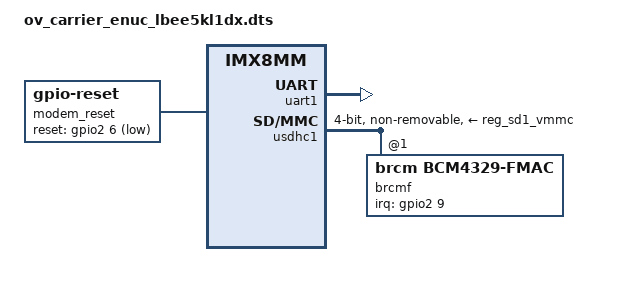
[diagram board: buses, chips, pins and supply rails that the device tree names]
/**
 * Portenta-M8 dtb overlay file
 * Arduino 2021
 * Enable modem LBEE5KL1DX serial on Arduino eNUC carrier board
 * with RTS CTS and modem reset
 * Gpios:
 * gpio-reset controls modem reset active low
 */

/dts-v1/;
/plugin/;

#include <dt-bindings/gpio/gpio.h>
#include <dt-bindings/interrupt-controller/arm-gic.h>
#include "imx8mm-pinfunc.h"

/ {
	compatible = "fsl,imx8mm-evk", "fsl,imx8mm";

	fragment@0 {
		target = <&iomuxc>;
		__overlay__ {
			imx8mm {
				pinctrl_uart1: uart1grp {
					fsl,pins = <
						MX8MM_IOMUXC_UART1_RXD_UART1_DCE_RX     0x140
						MX8MM_IOMUXC_UART1_TXD_UART1_DCE_TX     0x140
						MX8MM_IOMUXC_UART3_RXD_UART1_DCE_CTS_B  0x140
						MX8MM_IOMUXC_UART3_TXD_UART1_DCE_RTS_B  0x140
						MX8MM_IOMUXC_SD1_DATA4_GPIO2_IO6        0x19 // BT_REG_ON
					>;
				};

				pinctrl_usdhc1_gpio: usdhc1grpgpio {
					fsl,pins = <
						MX8MM_IOMUXC_SD1_RESET_B_GPIO2_IO10         0x41 // WL_REG_ON
						MX8MM_IOMUXC_GPIO1_IO00_ANAMIX_REF_CLK_32K  0x141 // REF_CLK_32K
					>;
				};

				pinctrl_usdhc1: usdhc1grp {
					fsl,pins = <
						MX8MM_IOMUXC_SD1_CLK_USDHC1_CLK		0x190
						MX8MM_IOMUXC_SD1_CMD_USDHC1_CMD		0x1d0
						MX8MM_IOMUXC_SD1_DATA0_USDHC1_DATA0	0x1d0
						MX8MM_IOMUXC_SD1_DATA1_USDHC1_DATA1	0x1d0
						MX8MM_IOMUXC_SD1_DATA2_USDHC1_DATA2	0x1d0
						MX8MM_IOMUXC_SD1_DATA3_USDHC1_DATA3	0x1d0
					>;
				};

				pinctrl_usdhc1_100mhz: usdhc1grp100mhz {
					fsl,pins = <
						MX8MM_IOMUXC_SD1_CLK_USDHC1_CLK		0x194
						MX8MM_IOMUXC_SD1_CMD_USDHC1_CMD		0x1d4
						MX8MM_IOMUXC_SD1_DATA0_USDHC1_DATA0	0x1d4
						MX8MM_IOMUXC_SD1_DATA1_USDHC1_DATA1	0x1d4
						MX8MM_IOMUXC_SD1_DATA2_USDHC1_DATA2	0x1d4
						MX8MM_IOMUXC_SD1_DATA3_USDHC1_DATA3	0x1d4
					>;
				};

				pinctrl_usdhc1_200mhz: usdhc1grp200mhz {
					fsl,pins = <
						MX8MM_IOMUXC_SD1_CLK_USDHC1_CLK		0x196
						MX8MM_IOMUXC_SD1_CMD_USDHC1_CMD		0x1d6
						MX8MM_IOMUXC_SD1_DATA0_USDHC1_DATA0	0x1d6
						MX8MM_IOMUXC_SD1_DATA1_USDHC1_DATA1	0x1d6
						MX8MM_IOMUXC_SD1_DATA2_USDHC1_DATA2	0x1d6
						MX8MM_IOMUXC_SD1_DATA3_USDHC1_DATA3	0x1d6
					>;
				};
			};
		};
	};

	modem_reset: modem-reset {
		compatible = "gpio-reset";
		reset-gpios = <&gpio2 6 GPIO_ACTIVE_LOW>;
		reset-delay-us = <2000>;
		reset-post-delay-ms = <40>;
		#reset-cells = <0>;
	};

	fragment@1 {
		target = <&uart1>;
		__overlay__ {
			pinctrl-names = "default";
			pinctrl-0 = <&pinctrl_uart1>;
			uart-has-rtscts;
			resets = <&modem_reset>;
			status = "okay";
		};
	};

	fragment@2 {
		target = <&usdhc1>;
		__overlay__ {
			#address-cells = <1>;
			#size-cells = <0>;
			pinctrl-names = "default", "state_100mhz", "state_200mhz";
			pinctrl-0 = <&pinctrl_usdhc1>, <&pinctrl_usdhc1_gpio>;
			pinctrl-1 = <&pinctrl_usdhc1_100mhz>, <&pinctrl_usdhc1_gpio>;
			pinctrl-2 = <&pinctrl_usdhc1_200mhz>, <&pinctrl_usdhc1_gpio>;
			bus-width = <4>;
			vmmc-supply = <&reg_sd1_vmmc>;
			pm-ignore-notify;
			keep-power-in-suspend;
			non-removable;
			status = "okay";

			brcmf: bcrmf@1 {
				reg = <1>;
				compatible = "brcm,bcm4329-fmac";
				interrupt-parent = <&gpio2>;
				interrupts = <9 IRQ_TYPE_LEVEL_HIGH>;
				interrupt-names = "host-wake";
			};
		};
	};
};
